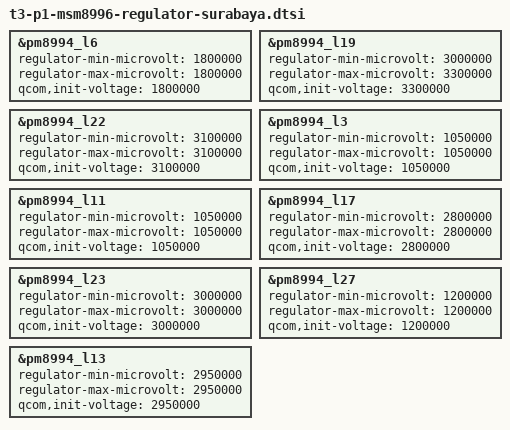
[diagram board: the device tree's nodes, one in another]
&pm8994_l6 {
	regulator-min-microvolt = <1800000>;
	regulator-max-microvolt = <1800000>;
	qcom,init-voltage = <1800000>;
};

&pm8994_l19 {
		regulator-min-microvolt = <3000000>;
		regulator-max-microvolt = <3300000>;
		qcom,init-voltage = <3300000>;
};

&pm8994_l22 {
	regulator-min-microvolt = <3100000>;
	regulator-max-microvolt = <3100000>;
	qcom,init-voltage = <3100000>;
};

&pm8994_l3 {
	regulator-min-microvolt = <1050000>;
	regulator-max-microvolt = <1050000>;
	qcom,init-voltage = <1050000>;
};

&pm8994_l11 {
	regulator-min-microvolt = <1050000>;
	regulator-max-microvolt = <1050000>;
	qcom,init-voltage = <1050000>;
};

&pm8994_l17 {
	regulator-min-microvolt = <2800000>;
	regulator-max-microvolt = <2800000>;
	qcom,init-voltage = <2800000>;
};

&pm8994_l23 {
	regulator-min-microvolt = <3000000>;
	regulator-max-microvolt = <3000000>;
	qcom,init-voltage = <3000000>;
};

&pm8994_l27 {
	regulator-min-microvolt = <1200000>;
	regulator-max-microvolt = <1200000>;
	qcom,init-voltage = <1200000>;
};

&pm8994_l13 {
	regulator-min-microvolt = <2950000>;
	regulator-max-microvolt = <2950000>;
	qcom,init-voltage = <2950000>;
};
